AUTOSAR XML (schema 4-0-3)
package /ComponentTypes
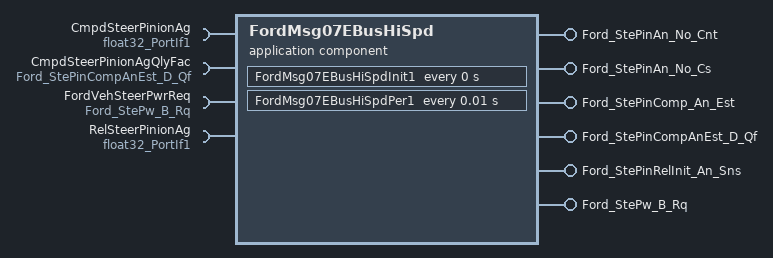
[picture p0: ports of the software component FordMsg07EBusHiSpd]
  application sw component type FordMsg07EBusHiSpd
    6 x provide port:
      Ford_StePinAn_No_Cnt: nonqueued-sender-com-spec{data-element=Ford_StePinAn_No_Cnt, init-value=0}, provided-interface=Ford_StePinAn_No_Cnt  # This signal increments by 1 in every periodic cycle and set to zero once crosses 15.Customer datatype should be used. Datatype:Ford_StePinAn_No_Cnt with the range of 0 to 15.
      Ford_StePinAn_No_Cs: nonqueued-sender-com-spec{data-element=Ford_StePinAn_No_Cs, init-value=0}, provided-interface=Ford_StePinAn_No_Cs  # Calculated by using the least significant 8 bits of the sum of the least significant 8 bits of the Steering Pinion Relative Angle signal checksum and the least significant 8 bits of the Steering Pinion Angle Counter signal checksum.Customer datatype should be used. Datatype:Ford_StePinAn_No_Cs with the range of 0 to 255.
      Ford_StePinComp_An_Est: nonqueued-sender-com-spec{data-element=Ford_StePinComp_An_Est, init-value=0}, provided-interface=Ford_StePinComp_An_Est  # Processed signal of input Compensted Steering Pinion Angle.Customer datatype should be used. Datatype: Ford_StePinComp_An_Est with the range of 0 to 32767.
      Ford_StePinCompAnEst_D_Qf: nonqueued-sender-com-spec{data-element=Ford_StePinCompAnEst_D_Qf, init-value=1}, provided-interface=Ford_StePinCompAnEst_D_Qf  # Processed signal of input CmpdSteerPinionAgQlyFac.Customer datatype should be used. Datatype:Ford_StePinCompAnEst_D_Qf.Elements are 0 - "Cx0'_Faulty", 1 - "Cx1_No_Data_Exists", 2 -"Cx2_Degraded", 3 - "Cx3_OK"
      Ford_StePinRelInit_An_Sns: nonqueued-sender-com-spec{data-element=Ford_StePinRelInit_An_Sns, init-value=65535}, provided-interface=Ford_StePinRelInit_An_Sns  # Processed signal of input RelSteerPinionAg.Customer datatype should be used. Datatype: Ford_StePinRelInit_An_Sns with range of 0 to 65535.
      Ford_StePw_B_Rq: nonqueued-sender-com-spec{data-element=Ford_StePw_B_Rq, init-value=0}, provided-interface=Ford_StePw_B_Rq  # Processed value of Steering Power Request.Customer datatype should be used.Datatype: Ford_StePw_B_Rq. Elements are 0 - "Cx0_No", 1 - "Cx1_Yes"
    4 x require port:
      CmpdSteerPinionAg: nonqueued-receiver-com-spec{data-element=Val, filter=data-filter-type=ALWAYS, init-value=0}, required-interface=float32_PortIf1
      CmpdSteerPinionAgQlyFac: nonqueued-receiver-com-spec{data-element=Ford_StePinCompAnEst_D_Qf, filter=data-filter-type=ALWAYS, init-value=1}, required-interface=Ford_StePinCompAnEst_D_Qf  # Compensted Steering Pinion Angle Quality Factor is received as input from EPS and processed to CAN Bus
      FordVehSteerPwrReq: nonqueued-receiver-com-spec{data-element=Ford_StePw_B_Rq, filter=data-filter-type=ALWAYS, init-value=0}, required-interface=Ford_StePw_B_Rq
      RelSteerPinionAg: nonqueued-receiver-com-spec{data-element=Val, filter=data-filter-type=ALWAYS, init-value=3353.5}, required-interface=float32_PortIf1
    behavior FordMsg07EBusHiSpd_InternalBehavior
      ar-typed-per-instance-memorys:
        data SteerPinionAgCntrPrev: sw-calibration-access=READ-ONLY, type=uint8
      timing event FordMsg07EBusHiSpd_InitEvent: start-on-event=FordMsg07EBusHiSpdInit1, period=0
      timing event TMT_FordMsg07EBusHiSpdPer1: start-on-event=FordMsg07EBusHiSpdPer1, period=0.01
      port-api-options:
        enable-take-address=false, indirect-api=false, port=CmpdSteerPinionAgQlyFac
        enable-take-address=false, indirect-api=false, port=Ford_StePinAn_No_Cnt
        enable-take-address=false, indirect-api=false, port=Ford_StePinAn_No_Cs
        enable-take-address=false, indirect-api=false, port=Ford_StePinComp_An_Est
        enable-take-address=false, indirect-api=false, port=Ford_StePinCompAnEst_D_Qf
        enable-take-address=false, indirect-api=false, port=Ford_StePinRelInit_An_Sns
        enable-take-address=false, indirect-api=false, port=RelSteerPinionAg
      runnable FordMsg07EBusHiSpdInit1
      runnable FordMsg07EBusHiSpdPer1
        data-receive-point-by-arguments:
          4 x access:
            REC_CmpdSteerPinionAg_Val: accessed-variable=CmpdSteerPinionAg.Val
            REC_CmpdSteerPinionAgQlyFac_Ford_StePinCompAnEst_D_Qf: accessed-variable=CmpdSteerPinionAgQlyFac.Ford_StePinCompAnEst_D_Qf
            REC_FordVehSteerPwrReq_Ford_StePw_B_Rq: accessed-variable=FordVehSteerPwrReq.Ford_StePw_B_Rq
            REC_RelSteerPinionAg_Val: accessed-variable=RelSteerPinionAg.Val
        data-send-points:
          6 x access:
            SEND_Ford_StePinAn_No_Cnt_Ford_StePinAn_No_Cnt: accessed-variable=Ford_StePinAn_No_Cnt.Ford_StePinAn_No_Cnt
            SEND_Ford_StePinAn_No_Cs_Ford_StePinAn_No_Cs: accessed-variable=Ford_StePinAn_No_Cs.Ford_StePinAn_No_Cs
            SEND_Ford_StePinComp_An_Est_Ford_StePinComp_An_Est: accessed-variable=Ford_StePinComp_An_Est.Ford_StePinComp_An_Est
            SEND_Ford_StePinCompAnEst_D_Qf1_Ford_StePinCompAnEst_D_Qf: accessed-variable=Ford_StePinCompAnEst_D_Qf.Ford_StePinCompAnEst_D_Qf
            SEND_Ford_StePinRelInit_An_Sns_Ford_StePinRelInit_An_Sns: accessed-variable=Ford_StePinRelInit_An_Sns.Ford_StePinRelInit_An_Sns
            SEND_Ford_StePw_B_Rq1_Ford_StePw_B_Rq: accessed-variable=Ford_StePw_B_Rq.Ford_StePw_B_Rq
  swc implementation FordMsg07EBusHiSpd_Implementation: behavior=FordMsg07EBusHiSpd_InternalBehavior
    code-descriptors:
      code Default: artifact-descriptors=autosar-engineering-object={short-label=Default, category=SWSRC}
